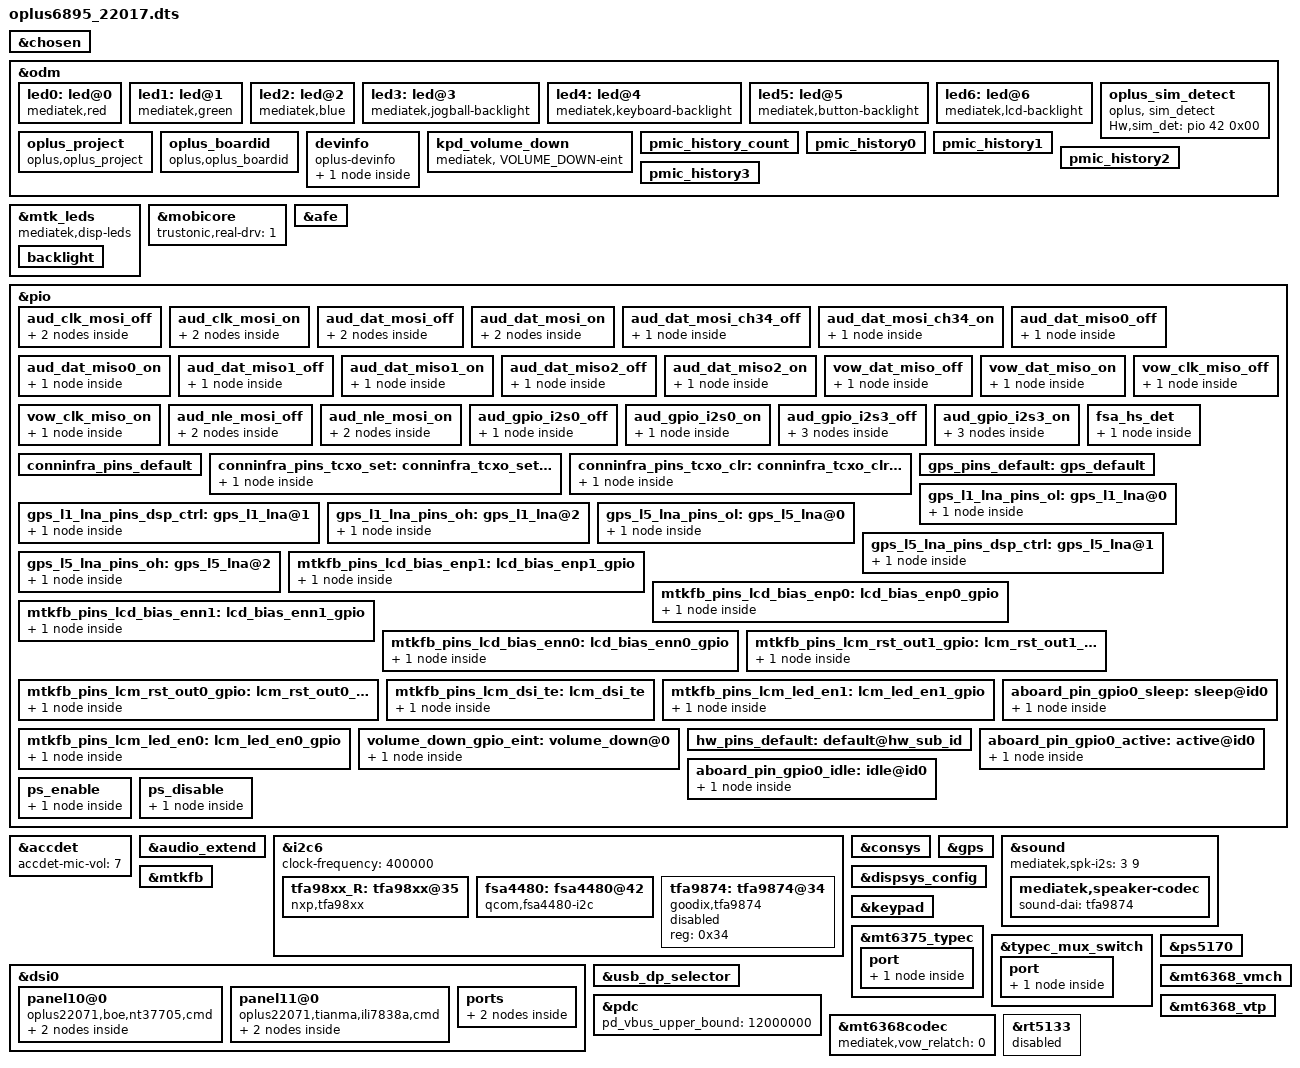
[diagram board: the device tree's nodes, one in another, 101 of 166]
// SPDX-License-Identifier: (GPL-2.0 OR MIT)
/*
 * Copyright (C) 2020 MediaTek Inc.
 * Author: Chun-Hung Wu <chun-hung.wu@mediatek.com>
 */
/dts-v1/;
/plugin/;
#include <dt-bindings/interrupt-controller/arm-gic.h>
#include <dt-bindings/interrupt-controller/irq.h>
#include <dt-bindings/phy/phy.h>
#include <dt-bindings/pinctrl/mt6895-pinfunc.h>
#include "mediatek/oplus_charge_22017.dtsi"

/* #ifdef CONFIG_UFF_FINGERPRINT */
#include "mediatek/oplus_uff_22017.dtsi"
/* #endif CONFIG_UFF_FINGERPRINT */

//#ifdef OPLUS_FEATURE_SENSOR
#include "mediatek/oplus_sensor_22017.dtsi"
//#endif

//#ifdef OPLUS_FEATURE_TP_BASIC
#include "mediatek/cust_mt6895_taibai_msdc.dtsi"
//#endif

//#ifdef OPLUS_FEATURE_SENSOR
#include "mediatek/oplus_tp_22017.dtsi"
//#endif

&chosen {
	bootargs_ext = "console=tty0 root=/dev/ram \
		loglevel=8 \
		androidboot.hardware=mt6895 \
		log_buf_len=2m \
		initcall_debug=1 ";
};

&odm {
	led0:led@0 {
                compatible = "mediatek,red";
                led_mode = <0>;
                data = <1>;
                pwm_config = <0 0 0 0 0>;
        };
        led1:led@1 {
                compatible = "mediatek,green";
                led_mode = <0>;
                data = <1>;
                pwm_config = <0 0 0 0 0>;
        };
        led2:led@2 {
                compatible = "mediatek,blue";
                led_mode = <0>;
                data = <1>;
                pwm_config = <0 0 0 0 0>;
        };
        led3:led@3 {
                compatible = "mediatek,jogball-backlight";
                led_mode = <0>;
                data = <1>;
                pwm_config = <0 0 0 0 0>;
        };
        led4:led@4 {
                compatible = "mediatek,keyboard-backlight";
                led_mode = <0>;
                data = <1>;
                pwm_config = <0 0 0 0 0>;
        };
        led5:led@5 {
                compatible = "mediatek,button-backlight";
                led_mode = <0>;
                data = <1>;
                pwm_config = <0 0 0 0 0>;
        };
        led6:led@6 {
                compatible = "mediatek,lcd-backlight";
                led_mode = <4>;
                data = <1>;
                pwm_config = <0 1 0 0 0>;
        };
};

&mtk_leds {
	compatible = "mediatek,disp-leds";
	backlight {
		label = "lcd-backlight";
		led_mode = <4>;
		max-brightness = <10239>;
		max-hw-brightness = <10239>;
		led-bits = <13>;
		};
};

/*Trustonic Mobicore real driver*/
&mobicore {
    trustonic,real-drv=<1>;
};

/* AUDIO GPIO standardization start */
&afe {
	pinctrl-names = "aud_clk_mosi_off",
			"aud_clk_mosi_on",
			"aud_dat_mosi_off",
			"aud_dat_mosi_on",
			"aud_dat_mosi_ch34_off",
			"aud_dat_mosi_ch34_on",
			"aud_dat_miso0_off",
			"aud_dat_miso0_on",
			"aud_dat_miso1_off",
			"aud_dat_miso1_on",
			"aud_dat_miso2_off",
			"aud_dat_miso2_on",
			"vow_dat_miso_off",
			"vow_dat_miso_on",
			"vow_clk_miso_off",
			"vow_clk_miso_on",
			"aud_gpio_i2s3_off",
			"aud_gpio_i2s3_on",
			"aud_gpio_i2s0_off",
			"aud_gpio_i2s0_on";
	pinctrl-0 = <&aud_clk_mosi_off>;
	pinctrl-1 = <&aud_clk_mosi_on>;
	pinctrl-2 = <&aud_dat_mosi_off>;
	pinctrl-3 = <&aud_dat_mosi_on>;
	pinctrl-4 = <&aud_dat_mosi_ch34_off>;
	pinctrl-5 = <&aud_dat_mosi_ch34_on>;
	pinctrl-6 = <&aud_dat_miso0_off>;
	pinctrl-7 = <&aud_dat_miso0_on>;
	pinctrl-8 = <&aud_dat_miso1_off>;
	pinctrl-9 = <&aud_dat_miso1_on>;
	pinctrl-10 = <&aud_dat_miso2_off>;
	pinctrl-11 = <&aud_dat_miso2_on>;
	pinctrl-12 = <&vow_dat_miso_off>;
	pinctrl-13 = <&vow_dat_miso_on>;
	pinctrl-14 = <&vow_clk_miso_off>;
	pinctrl-15 = <&vow_clk_miso_on>;
	pinctrl-16 = <&aud_gpio_i2s3_off>;
	pinctrl-17 = <&aud_gpio_i2s3_on>;
	pinctrl-18 = <&aud_gpio_i2s0_off>;
	pinctrl-19 = <&aud_gpio_i2s0_on>;
};
&pio {
	aud_clk_mosi_off: aud_clk_mosi_off {
		pins_cmd1_dat {
			pinmux = <PINMUX_GPIO202__FUNC_GPIO202>;
			input-enable;
			bias-pull-down;
		};
		pins_cmd2_dat {
			pinmux = <PINMUX_GPIO203__FUNC_GPIO203>;
			input-enable;
			bias-pull-down;
		};
	};
	aud_clk_mosi_on: aud_clk_mosi_on {
		pins_cmd1_dat {
			pinmux = <PINMUX_GPIO202__FUNC_AUD_CLK_MOSI>;
			input-schmitt-enable;
			bias-disable;
		};
		pins_cmd2_dat {
			pinmux = <PINMUX_GPIO203__FUNC_AUD_SYNC_MOSI>;
			input-schmitt-enable;
			bias-disable;
		};
};
	aud_dat_mosi_off: aud_dat_mosi_off {
		pins_cmd1_dat {
			pinmux = <PINMUX_GPIO204__FUNC_GPIO204>;
			input-enable;
			bias-pull-down;
		};
		pins_cmd2_dat {
			pinmux = <PINMUX_GPIO205__FUNC_GPIO205>;
			input-enable;
			bias-pull-down;
		};
};
	aud_dat_mosi_on: aud_dat_mosi_on {
		pins_cmd1_dat {
			pinmux = <PINMUX_GPIO204__FUNC_AUD_DAT_MOSI0>;
			input-schmitt-enable;
			bias-disable;
		};
		pins_cmd2_dat {
			pinmux = <PINMUX_GPIO205__FUNC_AUD_DAT_MOSI1>;
			input-schmitt-enable;
			bias-disable;
		};
};
	aud_dat_mosi_ch34_off: aud_dat_mosi_ch34_off {
		pins_cmd1_dat {
			pinmux = <PINMUX_GPIO206__FUNC_GPIO206>;
			input-enable;
			bias-pull-down;
		};
	};
	aud_dat_mosi_ch34_on: aud_dat_mosi_ch34_on {
		pins_cmd1_dat {
			pinmux = <PINMUX_GPIO206__FUNC_AUD_DAT_MOSI2>;
			input-schmitt-enable;
			bias-disable;
		};
	};
	aud_dat_miso0_off: aud_dat_miso0_off {
		pins_cmd1_dat {
			pinmux = <PINMUX_GPIO209__FUNC_GPIO209>;
			input-enable;
			bias-pull-down;
		};
	};
	aud_dat_miso0_on: aud_dat_miso0_on {
		pins_cmd1_dat {
			pinmux = <PINMUX_GPIO209__FUNC_AUD_DAT_MISO0>;
			input-schmitt-enable;
			bias-disable;
		};
	};
	aud_dat_miso1_off: aud_dat_miso1_off {
		pins_cmd1_dat {
			pinmux = <PINMUX_GPIO210__FUNC_GPIO210>;
			input-enable;
			bias-disable;
		};
	};
	aud_dat_miso1_on: aud_dat_miso1_on {
		pins_cmd1_dat {
			pinmux = <PINMUX_GPIO210__FUNC_AUD_DAT_MISO1>;
			input-schmitt-enable;
			bias-disable;
		};
	};
	aud_dat_miso2_off: aud_dat_miso2_off {
		pins_cmd1_dat {
			pinmux = <PINMUX_GPIO211__FUNC_GPIO211>;
			input-enable;
			bias-pull-down;
		};
	};
	aud_dat_miso2_on: aud_dat_miso2_on {
		pins_cmd1_dat {
			pinmux = <PINMUX_GPIO211__FUNC_AUD_DAT_MISO2>;
			input-schmitt-enable;
			bias-disable;
		};
	};
	vow_dat_miso_off: vow_dat_miso_off {
		pins_cmd1_dat {
			pinmux = <PINMUX_GPIO209__FUNC_GPIO209>;
			input-enable;
			bias-pull-down;
		};
	};
	vow_dat_miso_on: vow_dat_miso_on {
		pins_cmd1_dat {
			pinmux = <PINMUX_GPIO209__FUNC_VOW_DAT_MISO>;
			input-schmitt-enable;
			bias-disable;
		};
	};
	vow_clk_miso_off: vow_clk_miso_off {
		pins_cmd1_dat {
			pinmux = <PINMUX_GPIO210__FUNC_GPIO210>;
			input-enable;
			bias-pull-down;
		};
	};
	vow_clk_miso_on: vow_clk_miso_on {
		pins_cmd1_dat {
			pinmux = <PINMUX_GPIO210__FUNC_VOW_CLK_MISO>;
			input-schmitt-enable;
			bias-disable;
		};
	};
	aud_nle_mosi_off: aud_nle_mosi_off {
		pins_cmd1_dat {
			pinmux = <PINMUX_GPIO207__FUNC_GPIO207>;
			input-enable;
			bias-pull-down;
		};
		pins_cmd2_dat {
			pinmux = <PINMUX_GPIO208__FUNC_GPIO208>;
			input-enable;
			bias-pull-down;
		};
	};
	aud_nle_mosi_on: aud_nle_mosi_on {
		pins_cmd1_dat {
			pinmux = <PINMUX_GPIO207__FUNC_AUD_NLE_MOSI1>;
			input-schmitt-enable;
			bias-disable;
		};
		pins_cmd2_dat {
			pinmux = <PINMUX_GPIO208__FUNC_AUD_NLE_MOSI0>;
			input-schmitt-enable;
			bias-disable;
		};
	};
	aud_gpio_i2s0_off: aud_gpio_i2s0_off {
		pins_cmd1_dat {
			pinmux = <PINMUX_GPIO117__FUNC_GPIO117>;
			input-enable;
			bias-pull-down;
		};
	};
	aud_gpio_i2s0_on: aud_gpio_i2s0_on {
		pins_cmd1_dat {
			pinmux = <PINMUX_GPIO117__FUNC_I2S0_DI>;
			input-schmitt-enable;
			bias-disable;
		};
	};
	aud_gpio_i2s3_off: aud_gpio_i2s3_off {
		pins_cmd1_dat {
			pinmux = <PINMUX_GPIO115__FUNC_GPIO115>;
			input-enable;
			bias-pull-down;
		};
		pins_cmd2_dat {
			pinmux = <PINMUX_GPIO116__FUNC_GPIO116>;
			input-enable;
			bias-pull-down;
		};
		pins_cmd3_dat {
			pinmux = <PINMUX_GPIO118__FUNC_GPIO118>;
			input-enable;
			bias-pull-down;
		};
	};
	aud_gpio_i2s3_on: aud_gpio_i2s3_on {
		pins_cmd1_dat {
			pinmux = <PINMUX_GPIO115__FUNC_I2S3_BCK>;
			input-schmitt-enable;
			bias-disable;
		};
		pins_cmd2_dat {
			pinmux = <PINMUX_GPIO116__FUNC_I2S3_LRCK>;
			input-schmitt-enable;
			bias-disable;
		};
		pins_cmd3_dat {
			pinmux = <PINMUX_GPIO118__FUNC_I2S3_DO>;
			input-schmitt-enable;
			bias-disable;
		};
	};
};
/* AUDIO GPIO standardization end */
//#ifdef OPLUS_ARCH_EXTENDS

&accdet {
	accdet-mic-vol = <7>;
};

&audio_extend {
	//for nxp speaker
	oplus,speaker-vendor = "nxp";
	oplus,speaker-i2s-id = <3>;
	oplus,speaker-i2s-id-in = <0>;
	oplus,speaker-codec-name = "tfa98xx.6-0035";
	oplus,speaker-codec-dai-name = "tfa98xx-aif-6-35";
};

&i2c6 {
	clock-frequency = <400000>;

	tfa98xx_R: tfa98xx@35 {
		compatible = "nxp,tfa98xx";
		reg = <0x35>;
		reset-gpio = <&pio 158 0>;
		tfa_min_range = <5000>;
		tfa_max_range = <8000>;
		tfa_channel = <1>;
                is_use_freq;
		status = "okay";
	};
};

&i2c6 {
	fsa4480: fsa4480@42 {
		compatible = "qcom,fsa4480-i2c";
		reg = <0x42>;
		pinctrl-names = "default";
		pinctrl-0 = <&fsa_hs_det>;
		fsa4480,hs-det-gpio = <&pio 53 0>;
	};
};

&pio {
	fsa_hs_det: fsa_hs_det {
		pins_cmd_dat {
			pinmux = <PINMUX_GPIO53__FUNC_GPIO53>;
			slew-rate = <1>;  /*direction 0:in, 1:out*/
			output-high;
		};
	};
};
//#endif /*OPLUS_ARCH_EXTENDS*/

&i2c6 {
	tfa9874: tfa9874@34 {
		compatible = "goodix,tfa9874";
		#sound-dai-cells = <0>;
		reg = <0x34>;
		status = "disabled";
	};
};
/*
&i2c6 {
	spk: speaker_amp@5c {
		compatible = "richtek,rt5512";
		#sound-dai-cells = <0>;
		reg = <0x5c>;
		status = "okay";
		sound-name-prefix = "Left";
	};
};
*/

/* CONNSYS TCXO GPIO start */
&consys {
	tcxo_support = "false";
	pinctrl-names = "default", "conninfra_tcxo_set", "conninfra_tcxo_clr";
	pinctrl-0 = <&conninfra_pins_default>;
	pinctrl-1 = <&conninfra_pins_tcxo_set>;
	pinctrl-2 = <&conninfra_pins_tcxo_clr>;
	status = "okay";
};

&pio {
	conninfra_pins_default: conninfra_pins_default {
	};
	conninfra_pins_tcxo_set: conninfra_tcxo_set@gpio {
		pins_cmd_dat {
			pinmux = <PINMUX_GPIO108__FUNC_CONN_TCXOENA_REQ>;
		};
	};
	conninfra_pins_tcxo_clr: conninfra_tcxo_clr@gpio {
		pins_cmd_dat {
			pinmux = <PINMUX_GPIO108__FUNC_GPIO108>;
		};
	};
};
/* CONNSYS TCXO GPIO end */

/* GPS GPIO standardization start */
&pio {
	gps_pins_default: gps_default {
	};

	gps_l1_lna_pins_ol: gps_l1_lna@0 {
		pins_cmd_dat {
			pinmux = <PINMUX_GPIO176__FUNC_GPIO176>;
			output-low;
		};
	};
	gps_l1_lna_pins_dsp_ctrl: gps_l1_lna@1 {
		pins_cmd_dat {
			pinmux = <PINMUX_GPIO176__FUNC_GPS_L1_ELNA_EN>;
		};
	};
	gps_l1_lna_pins_oh: gps_l1_lna@2 {
		pins_cmd_dat {
			pinmux = <PINMUX_GPIO176__FUNC_GPIO176>;
			output-high;
		};
	};

	gps_l5_lna_pins_ol: gps_l5_lna@0 {
		pins_cmd_dat {
			pinmux = <PINMUX_GPIO177__FUNC_GPIO177>;
			output-low;
		};
	};
	gps_l5_lna_pins_dsp_ctrl: gps_l5_lna@1 {
		pins_cmd_dat {
			pinmux = <PINMUX_GPIO177__FUNC_GPS_L5_ELNA_EN>;
		};
	};
	gps_l5_lna_pins_oh: gps_l5_lna@2 {
		pins_cmd_dat {
			pinmux = <PINMUX_GPIO177__FUNC_GPIO177>;
			output-high;
		};
	};
};

&gps {
	pinctrl-names = "default",
		"gps_l1_lna_disable",
		"gps_l1_lna_dsp_ctrl",
		"gps_l1_lna_enable",
		"gps_l5_lna_disable",
		"gps_l5_lna_dsp_ctrl",
		"gps_l5_lna_enable";
	pinctrl-0 = <&gps_pins_default>;
	pinctrl-1 = <&gps_l1_lna_pins_ol>;
	pinctrl-2 = <&gps_l1_lna_pins_dsp_ctrl>;
	pinctrl-3 = <&gps_l1_lna_pins_oh>;
	pinctrl-4 = <&gps_l5_lna_pins_ol>;
	pinctrl-5 = <&gps_l5_lna_pins_dsp_ctrl>;
	pinctrl-6 = <&gps_l5_lna_pins_oh>;
	status = "okay";
};
/* GPS GPIO standardization end */

&sound {
	mediatek,spk-i2s = <3 9>;
	mediatek,speaker-codec {
		sound-dai = <&tfa9874>;
	};
};

&pio {
	mtkfb_pins_lcd_bias_enp1: lcd_bias_enp1_gpio {
		pins_cmd_dat {
			pinmux = <PINMUX_GPIO39__FUNC_GPIO39>;
			slew-rate = <1>;
			output-high;
		};
	};

	mtkfb_pins_lcd_bias_enp0: lcd_bias_enp0_gpio {
		pins_cmd_dat {
			pinmux = <PINMUX_GPIO39__FUNC_GPIO39>;
			slew-rate = <1>;
			output-low;
		};
	};

	mtkfb_pins_lcd_bias_enn1: lcd_bias_enn1_gpio {
		pins_cmd_dat {
			pinmux = <PINMUX_GPIO39__FUNC_GPIO39>;
			slew-rate = <1>;
			output-high;
		};
	};

	mtkfb_pins_lcd_bias_enn0: lcd_bias_enn0_gpio {
		pins_cmd_dat {
			pinmux = <PINMUX_GPIO39__FUNC_GPIO39>;
			slew-rate = <1>;
			output-low;
		};
	};

	mtkfb_pins_lcm_rst_out1_gpio: lcm_rst_out1_gpio {
		pins_cmd_dat {
			pinmux = <PINMUX_GPIO41__FUNC_GPIO41>;
			slew-rate = <1>;
			output-high;
		};
	};

	mtkfb_pins_lcm_rst_out0_gpio: lcm_rst_out0_gpio {
		pins_cmd_dat {
			pinmux = <PINMUX_GPIO41__FUNC_GPIO41>;
			slew-rate = <1>;
			output-low;
		};
	};
	mtkfb_pins_lcm_dsi_te: lcm_dsi_te {
		pins_cmd_dat {
			pinmux = <PINMUX_GPIO40__FUNC_DSI_TE>;
		};
	};

	mtkfb_pins_lcm_led_en1: lcm_led_en1_gpio {
		pins_cmd_dat {
			pinmux = <PINMUX_GPIO215__FUNC_GPIO215>;
			slew-rate = <1>;
			output-high;
		};
	};

	mtkfb_pins_lcm_led_en0: lcm_led_en0_gpio {
		pins_cmd_dat {
			pinmux = <PINMUX_GPIO215__FUNC_GPIO215>;
			slew-rate = <1>;
			output-low;
		};
	};
};

&odm {
//#ifdef OPLUS_FEATURE_TP_BASIC
    oplus_sim_detect {
        compatible = "oplus, sim_detect";
        Hw,sim_det = <&pio 42 0x00>;
    };
//#endif /* OPLUS_FEATURE_TP_BASIC */
};

&mtkfb {
	pinctrl-names = "lcd_bias_enp1_gpio", "lcd_bias_enp0_gpio",
		"lcd_bias_enn1_gpio", "lcd_bias_enn0_gpio",
		"lcm_rst_out1_gpio", "lcm_rst_out0_gpio",
		"mode_te_te", "lcm_led_en1_gpio", "lcm_led_en0_gpio";
	pinctrl-0 = <&mtkfb_pins_lcd_bias_enp1>;
	pinctrl-1 = <&mtkfb_pins_lcd_bias_enp0>;
	pinctrl-2 = <&mtkfb_pins_lcd_bias_enn1>;
	pinctrl-3 = <&mtkfb_pins_lcd_bias_enn0>;
	pinctrl-4 = <&mtkfb_pins_lcm_rst_out1_gpio>;
	pinctrl-5 = <&mtkfb_pins_lcm_rst_out0_gpio>;
	pinctrl-6 = <&mtkfb_pins_lcm_dsi_te>;
	pinctrl-7 = <&mtkfb_pins_lcm_led_en1>;
	pinctrl-8 = <&mtkfb_pins_lcm_led_en0>;

	status = "okay";
};
&dispsys_config {
	pinctrl-names =
		"lcm_rst_out1_gpio", "lcm_rst_out0_gpio",
		"mode_te_te";
	pinctrl-0 = <&mtkfb_pins_lcm_rst_out1_gpio>;
	pinctrl-1 = <&mtkfb_pins_lcm_rst_out0_gpio>;
	pinctrl-2 = <&mtkfb_pins_lcm_dsi_te>;
	status = "okay";
	support_mml_cmd_mode;

	helper-value = <0>, /*MTK_DRM_OPT_STAGE*/
	<1>, /*MTK_DRM_OPT_USE_CMDQ*/
	<1>, /*MTK_DRM_OPT_USE_M4U*/
	<1>, /*MTK_DRM_OPT_MMQOS_SUPPORT*/
	<1>, /*MTK_DRM_OPT_MMDVFS_SUPPORT*/
	<1>, /*MTK_DRM_OPT_SODI_SUPPORT*/
	<1>, /*MTK_DRM_OPT_IDLE_MGR*/
	<0>, /*MTK_DRM_OPT_IDLEMGR_SWTCH_DECOUPLE*/
	<1>, /*MTK_DRM_OPT_IDLEMGR_BY_REPAINT*/
	<0>, /*MTK_DRM_OPT_IDLEMGR_ENTER_ULPS*/
	<0>, /*MTK_DRM_OPT_IDLEMGR_KEEP_LP11*/
	<1>, /*MTK_DRM_OPT_DYNAMIC_RDMA_GOLDEN_SETTING*/
	<1>, /*MTK_DRM_OPT_IDLEMGR_DISABLE_ROUTINE_IRQ*/
	<0>, /*MTK_DRM_OPT_MET_LOG*/
	<1>, /*MTK_DRM_OPT_USE_PQ*/
	<1>, /*MTK_DRM_OPT_ESD_CHECK_RECOVERY*/
	<1>, /*MTK_DRM_OPT_ESD_CHECK_SWITCH*/
	<1>, /*MTK_DRM_OPT_PRESENT_FENCE*/
	<0>, /*MTK_DRM_OPT_RDMA_UNDERFLOW_AEE*/
	<1>, /*MTK_DRM_OPT_DSI_UNDERRUN_AEE*/
	<1>, /*MTK_DRM_OPT_HRT*/
	<1>, /*MTK_DRM_OPT_HRT_MODE*/
	<0>, /*MTK_DRM_OPT_DELAYED_TRIGGER*/
	<1>, /*MTK_DRM_OPT_OVL_EXT_LAYER*/
	<1>, /*MTK_DRM_OPT_AOD*/
	<1>, /*MTK_DRM_OPT_RPO*/
	<0>, /*MTK_DRM_OPT_DUAL_PIPE*/
	<0>, /*MTK_DRM_OPT_DC_BY_HRT*/
	<1>, /*MTK_DRM_OPT_OVL_WCG*/
	<0>, /*MTK_DRM_OPT_OVL_SBCH*/
	<1>, /*MTK_DRM_OPT_COMMIT_NO_WAIT_VBLANK*/
	<0>, /*MTK_DRM_OPT_MET*/
	<0>, /*MTK_DRM_OPT_REG_PARSER_RAW_DUMP*/
	<0>, /*MTK_DRM_OPT_VP_PQ*/
	<0>, /*MTK_DRM_OPT_GAME_PQ*/
	<0>, /*MTK_DRM_OPT_MMPATH*/
	<1>, /*MTK_DRM_OPT_HBM*/
	<0>, /*MTK_DRM_OPT_VDS_PATH_SWITCH*/
	<0>, /*MTK_DRM_OPT_LAYER_REC*/
	<0>, /*MTK_DRM_OPT_CLEAR_LAYER*/
	<1>, /*MTK_DRM_OPT_LFR*/
	<0>, /*MTK_DRM_OPT_SF_PF*/
	<1>, /*MTK_DRM_OPT_DYN_MIPI_CHANGE*/
	<1>, /*MTK_DRM_OPT_PRIM_DUAL_PIPE*/
	<1>, /*MTK_DRM_OPT_MSYNC2_0*/
	<1>, /*MTK_DRM_OPT_MML_PRIMARY*/
	<0>, /*MTK_DRM_OPT_DUAL_TE*/
	<1>; /*MTK_DRM_OPT_RES_SWITCH*/
};

&dsi0 {
	status = "okay";
	#address-cells = <1>;
	#size-cells = <0>;
	panel10@0 {
		compatible = "oplus22071,boe,nt37705,cmd";
		reg = <0>;
		vddr-enable-gpios = <&pio 120 0>;
		vddr-aod-en-gpios = <&pio 22 0>;
		3p0-enable-gpios = <&pio 20 0>;
		reset-gpios = <&pio 41 0>;
		//vmcldo-supply = <&mt6368_vmc>;
		vufsldo-supply = <&mt6363_vufs18>;
		//vmchldo-supply = <&mt6368_vmch>;
		pinctrl-names = "default";
		port {
			panel_in10: endpoint {
				remote-endpoint = <&dsi_out>;
			};
		};
	};
	panel11@0 {
		compatible = "oplus22071,tianma,ili7838a,cmd";
		reg = <1>;
		vddr-enable-gpios = <&pio 120 0>;
		vddr-aod-en-gpios = <&pio 22 0>;
		3p0-enable-gpios = <&pio 20 0>;
		reset-gpios = <&pio 41 0>;
		//vmcldo-supply = <&mt6368_vmc>;
		vufsldo-supply = <&mt6363_vufs18>;
		//vmchldo-supply = <&mt6368_vmch>;
		pinctrl-names = "default";
		port {
			panel_in11: endpoint {
				remote-endpoint = <&dsi_out>;
			};
		};
	};
	ports {
		port {
			dsi_out: endpoint {
				remote-endpoint = <&panel_in10>;
			};
		};
	};
};

&odm {
/*OPLUS_BUG_STABILITY oplus project start */
	oplus_project:oplus_project {
		compatible = "oplus,oplus_project";
	};
/*endif*/

	oplus_boardid:oplus_boardid {
		compatible = "oplus,oplus_boardid";
		oplus_boardid,dtsino="22017";//only one u32
		oplus_boardid,pcbmask="0xffff";//all mask 0xffff
	};
};

&odm {
	devinfo {
		compatible = "oplus-devinfo";
		pinctrl-names = "default", "aboard_gpio0_sleep", "aboard_gpio0_active", "aboard_gpio0_idle";
		pinctrl-0 = <&hw_pins_default>;
		pinctrl-1 = <&aboard_pin_gpio0_sleep>;
		pinctrl-2 = <&aboard_pin_gpio0_active>;
		pinctrl-3 = <&aboard_pin_gpio0_idle>;
		main-sub {
			use_tristate_gpio;
			compatible = "hw-match, main-sub";
			aboard-gpio0 = <&pio 50 0x00>;
			aboard-patterns = <0>;	/*0[high-resistance] 1[pull-down] 2[pull-up]*/
			/*main board*/
			match-projects = <22017>;
		};
	};

	kpd_volume_down:kpd_volume_down {
				compatible = "mediatek, VOLUME_DOWN-eint";
				interrupt-parent = <&pio>;
				interrupts = <127 IRQ_TYPE_EDGE_FALLING 127 0>;
				debounce = <32000>;
				status = "okay";
	};
	
	pmic_history_count:pmic_history_count {
	};
	pmic_history0:pmic_history0 {
	};
	pmic_history1:pmic_history1 {
	};
	pmic_history2:pmic_history2 {
	};
	pmic_history3:pmic_history3 {
	};
	
};

&keypad {
		keypad,volume-down = <&pio 127 0x00>;
		pinctrl-names = "volume_down_as_int";
		pinctrl-0 = <&volume_down_gpio_eint>;
		status = "okay";
};

&pio {
		volume_down_gpio_eint:volume_down@0{
				pins_cmd_dat {
						pinmux = <PINMUX_GPIO127__FUNC_GPIO127>;
						slew-rate = <0>;  /*direction 0:in, 1:out*/
						input-enable;
				};
		};

	hw_pins_default:default@hw_sub_id {
	};
	aboard_pin_gpio0_sleep:sleep@id0 {
		pins_cmd_dat {
			pinmux = <PINMUX_GPIO50__FUNC_GPIO50>;
			slew-rate = <0>;
			bias-pull-down=<MTK_PUPD_SET_R1R0_10>;
			input-enable;
		};
	};

	aboard_pin_gpio0_active:active@id0 {
		pins_cmd_dat {
			pinmux = <PINMUX_GPIO50__FUNC_GPIO50>;
			slew-rate = <0>;
			bias-pull-up=<MTK_PUPD_SET_R1R0_01>;
			input-enable;
		};
	};

	aboard_pin_gpio0_idle:idle@id0 {
		pins_cmd_dat {
			pinmux = <PINMUX_GPIO50__FUNC_GPIO50>;
			slew-rate = <0>;
			bias-disable;
			input-enable;
		};
	};
};

/* usb typec mux start */
&pio {

	ps_enable: ps_enable {
		pins_cmd_dat {
			//pinmux = <PINMUX_GPIO158__FUNC_GPIO158>;
			output-high;
		};
	};

	ps_disable: ps_disable {
		pins_cmd_dat {
			//pinmux = <PINMUX_GPIO158__FUNC_GPIO158>;
			output-low;
		};
	};

};

&mt6375_typec {
	port {
		tcpc_typec_usb: endpoint@0 {
			remote-endpoint = <&ssusb_mux>;
		};
	};
};

&typec_mux_switch {
	orientation-switch;
	mode-switch;
	accessory;
	port {
		ssusb_mux: endpoint@0 {
			remote-endpoint = <&tcpc_typec_usb>;
		};
	};
};

&ps5170 {
	pinctrl-names = "enable", "disable";
	pinctrl-0 = <&ps_enable>;
	pinctrl-1 = <&ps_disable>;
	status = "okay";
};

&usb_dp_selector {
	status = "okay";
};
/* usb typec mux end */

&pdc {
	pd_vbus_upper_bound = <12000000>;
};

/* volumedown */
/*
&gpio_keys {
        volumedown {
            label = "Volume_Down";
            linux,code = <114>;
            gpios = <&pio 127 1>;
            wakeup-source;
            debounce-interval = <5>;
        };
};
*/

&mt6368_vmch {
	regulator-min-microvolt = <3000000>;
	regulator-max-microvolt = <3000000>;
	//regulator-boot-on;
	//regulator-always-on;
};

&mt6368_vtp{
	regulator-min-microvolt = <1800000>;
	regulator-max-microvolt = <3000000>;
	//regulator-boot-on;
	//regulator-always-on;
};

&mt6368codec {
	mediatek,vow_relatch = <0>;
};

&rt5133 {
	status = "disabled";
};

//#include "mediatek/cust_mt6895_camera_v4l2.dtsi"
#include <oplus6895_22017/cust.dtsi>
#include "mediatek/nfc/mt6895_linhai_22017_sn110.dtsi"
#include "mediatek/cust_mt6895_linhai_camera_v4l2.dtsi"
#include "mediatek/cust_mt6895_taibai_cam_thermal.dtsi"
#include "mediatek/cust_mt6895_taibai_shell_thermal.dtsi"
/*End of this file, DO NOT ADD ANYTHING HERE*/
